# CW32F030 register map
Vendor: Wuhan Xinyuan Semiconductor Co.Ltd; Series: ARMCM0P; File version: 1.2
CW32F030C8xx,CW32F030F6P6,CW32F030F8V7, CW32F030K8xx
CPU: CM0+ r0p1, little endian, no MPU, no FPU, 3 interrupt priority bits
Registers are 32-bit, read-write, no defined reset value unless marked. A register's access mark holds for its fields unless they carry their own. Offsets are from the block's base; lines under a group give offsets from that group; [hi:lo] are bit positions; {n}, {i} and the like mark numbered series; 'fields as' and 'values as' point back to an identical list; <NAME> marks a mode.

## Memory map
0x40000400 GTIM1 size 0x344 — General Timer 1
0x40001000 GTIM2 size 0x344 — General Timer 2
0x40002800 RTC size 0x3C
0x40002C00 WWDT size 0xC
0x40003000 IWDT size 0x28
0x40003800 SPI2 size 0x1C
0x40004400 UART2 size 0x38
0x40004800 UART3 size 0x38
0x40005400 I2C1 size 0x2C
0x40005800 I2C2 size 0x2C
0x40010000 SYSCTRL size 0x78 — System Ctrl
0x40012400 ADC size 0x8C
0x40012A00 VC1 size 0x10
0x40012A10 VC2 size 0x10
0x40012A80 LVD size 0xC
0x40012C00 ATIM size 0x5C
0x40013000 SPI1 size 0x1C
0x40013800 UART1 size 0x38
0x40014000 GTIM3 size 0x344 — General Timer 3
0x40014400 GTIM4 size 0x344 — General Timer 4
0x40014800 BTIM1 size 0x24 — Base Timer 1
0x40014900 BTIM2 size 0x24 — Base Timer 2
0x40014A00 BTIM3 size 0x24 — Base Timer 3
0x40014C00 AWT size 0x20
0x40020000 DMA size 0xB4
0x40020020 DMACHANNEL1 size 0x14
0x40020040 DMACHANNEL2 size 0x14
0x40020060 DMACHANNEL3 size 0x14
0x40020080 DMACHANNEL4 size 0x14
0x400200A0 DMACHANNEL5 size 0x14
0x40022000 FLASH size 0x2C
0x40022400 RAM size 0x10
0x40023000 CRC size 0x10
0x48000000 GPIOA size 0x64
0x48000400 GPIOB size 0x64
0x48000800 GPIOC size 0x64
0x48001400 GPIOF size 0x64

## Interrupts
0 WDT (IWDT, WWDT) — Watch Dog Timer Interrupt
1 LVD — Low Voltage Detect Interrupt
2 RTC — Real Time Clock Interrupt
3 FLASHRAM (FLASH, RAM) — Flash/RAM Interrupt
4 RCC (SYSCTRL) — RCC Interupt
5 GPIOA — GPIOA Interrupt
6 GPIOB — GPIOB Interrupt
7 GPIOC — GPIOC Interrupt
8 GPIOF — GPIOF Interrupt
9 DMACH1 (DMA, DMACHANNEL1) — DMA Channel 1 Interrupt
10 DMACH23 (DMACHANNEL2, DMACHANNEL3) — DMA Channel 2/3 Interrupt
11 DMACH45 (DMACHANNEL4, DMACHANNEL5) — DMA Channel 2/3 Interrupt
12 ADC — ADC Interrupt
13 ATIM — Advanced Timer Interrupt
14 VC1 — Voltage Comparator 1 Interrupt
15 VC2 — Voltage Comparator 2 Interrupt
16 GTIM1 — General Timer1 Interrupt
17 GTIM2 — General Timer2 Interrupt
18 GTIM3 — General Timer3 Interrupt
19 GTIM4 — General Timer4 Interrupt
20 BTIM1 — Base Timer1 Interrupt
21 BTIM2 — Base Timer2 Interrupt
22 BTIM3 — Base Timer3 Interrupt
23 I2C1 — I2C1 Interrupt
24 I2C2 — I2C2 Interrput
25 SPI1 — SPI1 Interrupt
26 SPI2 — SPI2 Interrupt
27 UART1 — UART1 Interrupt
28 UART2 — UART2 Interrupt
29 UART3 — UART3 Interrupt
30 AWT — Auto Wakeup Timer Interrupt
31 FAULT (CRC) — FAULT Interrupt

## ADC
Base 0x40012400
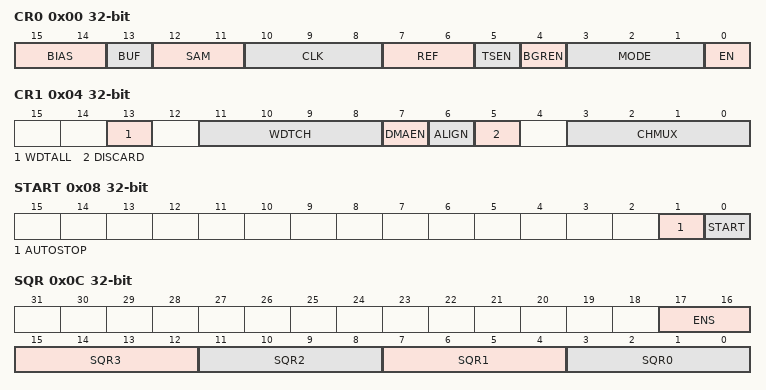
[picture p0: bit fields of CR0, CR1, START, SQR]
0x00 CR0 — Control register0
  [15:14] BIAS, [13] BUF, [12:11] SAM, [10:8] CLK, [7:6] REF, [5] TSEN, [4] BGREN, [3:1] MODE, [0] EN
0x04 CR1 — Control register1
  [13] WDTALL, [11:8] WDTCH, [7] DMAEN, [6] ALIGN, [5] DISCARD, [3:0] CHMUX
0x08 START
  [1] AUTOSTOP, [0] START
0x0C SQR
  [17:16] ENS, [4n+3:4n] SQR{n} (n=0..3)
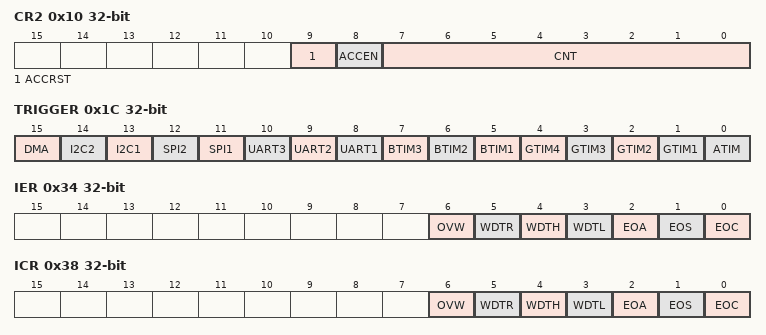
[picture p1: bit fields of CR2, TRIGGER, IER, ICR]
0x10 CR2 — Control register2
  [9] ACCRST, [8] ACCEN, [7:0] CNT
0x14 VTH
  [11:0] VTH
0x18 VTL
  [11:0] VTL
0x1C TRIGGER
  [15] DMA, [14] I2C2, [13] I2C1, [12] SPI2, [11] SPI1, [10] UART3, [9] UART2, [8] UART1, [7] BTIM3, [6] BTIM2, [5] BTIM1, [n] GTIM{n} (n=1..4), [0] ATIM
{0x20+4i} RESULT{i} ro (i=0..3)
  [15:0] RESULT
0x30 RESULTACC ro
  [23:0] RESULT
0x34 IER — Interrupt enable register
  [6] OVW, [5] WDTR, [4] WDTH, [3] WDTL, [2] EOA, [1] EOS, [0] EOC
0x38 ICR — Interrupt flag clear register
  [6] OVW, [5] WDTR, [4] WDTH, [3] WDTL, [2] EOA, [1] EOS, [0] EOC
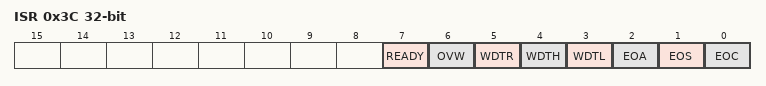
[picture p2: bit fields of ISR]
0x3C ISR ro — Interrupt status register
  [7] READY, [6] OVW, [5] WDTR, [4] WDTH, [3] WDTL, [2] EOA, [1] EOS, [0] EOC

## ATIM
Base 0x40012C00
0x00 ARR
  [15:0] ARR
0x04 CNT
  [15:0] CNT
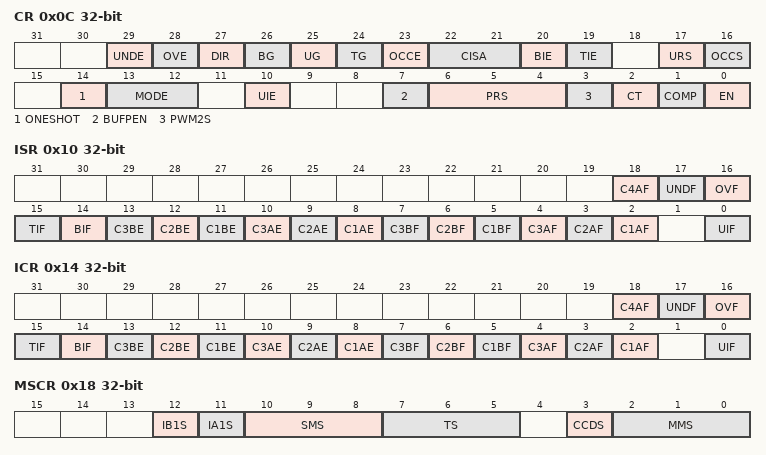
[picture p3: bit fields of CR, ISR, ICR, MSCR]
0x0C CR
  [29] UNDE
  [28] OVE
  [27] DIR
  [26] BG
  [25] UG
  [24] TG
  [23] OCCE
  [22:21] CISA
  [20] BIE
  [19] TIE
  [17] URS
  [16] OCCS
  [14] ONESHOT
  [13:12] MODE — Please keep 10/11
  [10] UIE
  [7] BUFPEN
  [6:4] PRS
  [3] PWM2S
  [2] CT
  [1] COMP
  [0] EN
0x10 ISR ro
  [18] C4AF, [17] UNDF, [16] OVF, [15] TIF, [14] BIF, [13] C3BE, [12] C2BE, [11] C1BE, [10] C3AE, [9] C2AE, [8] C1AE, [7] C3BF, [6] C2BF, [5] C1BF, [4] C3AF, [3] C2AF, [2] C1AF, [0] UIF
0x14 ICR
  fields as ISR
0x18 MSCR
  [12] IB1S, [11] IA1S, [10:8] SMS, [7:5] TS, [3] CCDS, [2:0] MMS
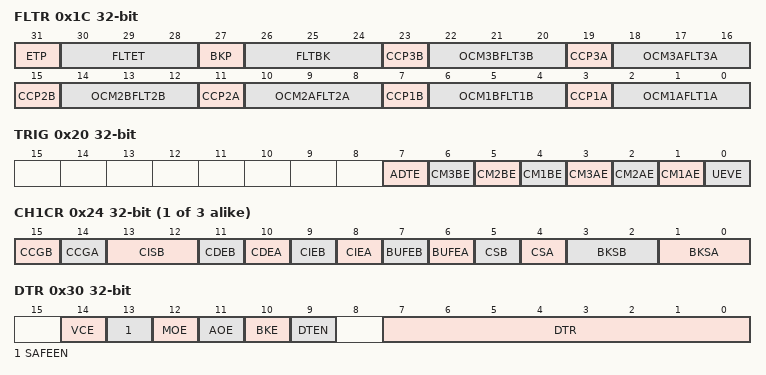
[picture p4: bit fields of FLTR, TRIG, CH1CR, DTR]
0x1C FLTR
  [31] ETP, [30:28] FLTET, [27] BKP, [26:24] FLTBK, [23] CCP3B, [22:20] OCM3BFLT3B, [19] CCP3A, [18:16] OCM3AFLT3A, [15] CCP2B, [14:12] OCM2BFLT2B, [11] CCP2A, [10:8] OCM2AFLT2A, [7] CCP1B, [6:4] OCM1BFLT1B, [3] CCP1A, [2:0] OCM1AFLT1A
0x20 TRIG
  [7] ADTE, [6] CM3BE, [5] CM2BE, [4] CM1BE, [3] CM3AE, [2] CM2AE, [1] CM1AE, [0] UEVE
{0x20+4i} CH{i}CR (i=1..3)
  [15] CCGB, [14] CCGA, [13:12] CISB, [11] CDEB, [10] CDEA, [9] CIEB, [8] CIEA, [7] BUFEB, [6] BUFEA, [5] CSB, [4] CSA, [3:2] BKSB, [1:0] BKSA
0x30 DTR
  [14] VCE, [13] SAFEEN, [12] MOE, [11] AOE, [10] BKE, [9] DTEN, [7:0] DTR
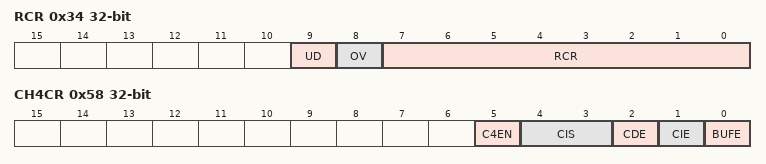
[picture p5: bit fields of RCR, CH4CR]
0x34 RCR
  [9] UD, [8] OV, [7:0] RCR
{0x34+8i} CH{i}CCRA (i=1..3)
  [15:0] CCR{i}A
{0x38+8i} CH{i}CCRB (i=1..3)
  [15:0] CCR{i}B
0x54 CH4CCR
  [15:0] CCR4
0x58 CH4CR
  [5] C4EN, [4:3] CIS, [2] CDE, [1] CIE, [0] BUFE
